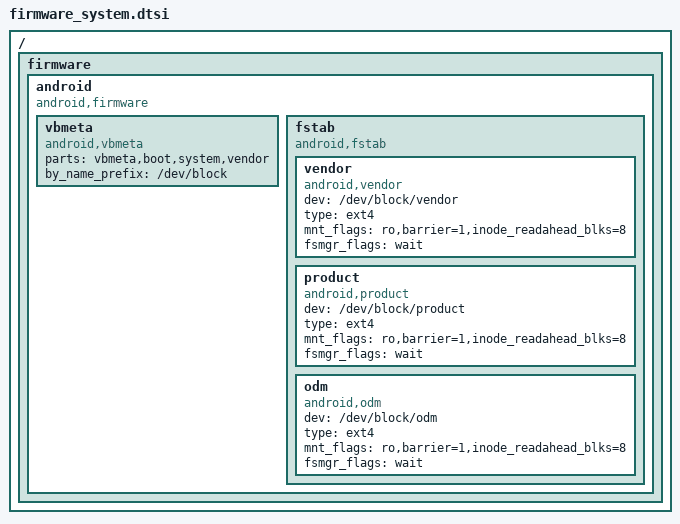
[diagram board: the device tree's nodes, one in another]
// SPDX-License-Identifier: (GPL-2.0+ OR MIT)
/*
 * Copyright (c) 2019 Amlogic, Inc. All rights reserved.
 */

/ {
	firmware {
		android {
			compatible = "android,firmware";
			vbmeta {
				compatible = "android,vbmeta";
				parts = "vbmeta,boot,system,vendor";
				by_name_prefix="/dev/block";
			};
		fstab {
			compatible = "android,fstab";

			vendor {
				compatible = "android,vendor";
				dev = "/dev/block/vendor";
				type = "ext4";
				mnt_flags = "ro,barrier=1,inode_readahead_blks=8";
				fsmgr_flags = "wait";
				};
			product {
				compatible = "android,product";
				dev = "/dev/block/product";
				type = "ext4";
				mnt_flags = "ro,barrier=1,inode_readahead_blks=8";
				fsmgr_flags = "wait";
				};
			odm {
				compatible = "android,odm";
				dev = "/dev/block/odm";
				type = "ext4";
				mnt_flags = "ro,barrier=1,inode_readahead_blks=8";
				fsmgr_flags = "wait";
				};
			};
		};
	};
};/* end of / */
